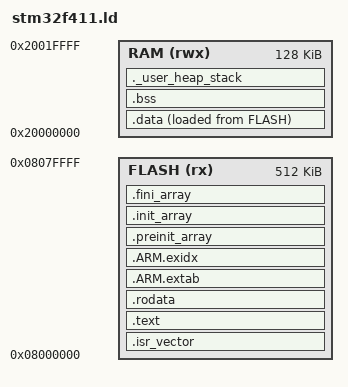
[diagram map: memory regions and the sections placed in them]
/*
 * STM32F411xE memory map: 512 KiB flash, 128 KiB SRAM.
 *
 * These two lengths are the whole point of the RAM check. The tensor arena,
 * the stack, the heap and every static live in RAM; the model weights stay in
 * flash and TFLite Micro reads them from there. If any of that stops fitting
 * an STM32F411, this link fails.
 */

ENTRY(Reset_Handler)

MEMORY
{
  FLASH (rx)  : ORIGIN = 0x08000000, LENGTH = 512K
  RAM   (rwx) : ORIGIN = 0x20000000, LENGTH = 128K
}

_stack_size = 0x2000;   /* 8 KiB main stack */
_heap_size  = 0x1000;   /* 4 KiB for newlib; TFLite Micro does not allocate */

SECTIONS
{
  .isr_vector :
  {
    . = ALIGN(4);
    KEEP(*(.isr_vector))
  } > FLASH

  .text :
  {
    . = ALIGN(4);
    *(.text*)
    *(.glue_7) *(.glue_7t) *(.eh_frame)
    KEEP(*(.init))
    KEEP(*(.fini))
    . = ALIGN(4);
  } > FLASH

  .rodata :
  {
    . = ALIGN(16);
    *(.rodata*)
    . = ALIGN(4);
  } > FLASH

  .ARM.extab : { *(.ARM.extab* .gnu.linkonce.armextab.*) } > FLASH
  .ARM.exidx :
  {
    __exidx_start = .;
    *(.ARM.exidx* .gnu.linkonce.armexidx.*)
    __exidx_end = .;
  } > FLASH

  .preinit_array :
  {
    PROVIDE_HIDDEN(__preinit_array_start = .);
    KEEP(*(.preinit_array*))
    PROVIDE_HIDDEN(__preinit_array_end = .);
  } > FLASH
  .init_array :
  {
    PROVIDE_HIDDEN(__init_array_start = .);
    KEEP(*(SORT(.init_array.*)))
    KEEP(*(.init_array*))
    PROVIDE_HIDDEN(__init_array_end = .);
  } > FLASH
  .fini_array :
  {
    PROVIDE_HIDDEN(__fini_array_start = .);
    KEEP(*(SORT(.fini_array.*)))
    KEEP(*(.fini_array*))
    PROVIDE_HIDDEN(__fini_array_end = .);
  } > FLASH

  _sidata = LOADADDR(.data);

  .data :
  {
    . = ALIGN(4);
    _sdata = .;
    *(.data*)
    . = ALIGN(4);
    _edata = .;
  } > RAM AT > FLASH

  .bss (NOLOAD) :
  {
    . = ALIGN(4);
    _sbss = .;
    __bss_start__ = _sbss;
    *(.bss*)
    *(COMMON)
    . = ALIGN(4);
    _ebss = .;
    __bss_end__ = _ebss;
  } > RAM

  /* Reserve the heap and the stack so the link fails if they do not fit. */
  ._user_heap_stack (NOLOAD) :
  {
    . = ALIGN(8);
    PROVIDE(end = .);
    PROVIDE(_end = .);
    . = . + _heap_size;
    . = ALIGN(8);
    _sstack = .;
    . = . + _stack_size;
    . = ALIGN(8);
    _estack = .;
  } > RAM

  .ARM.attributes 0 : { *(.ARM.attributes) }
}
